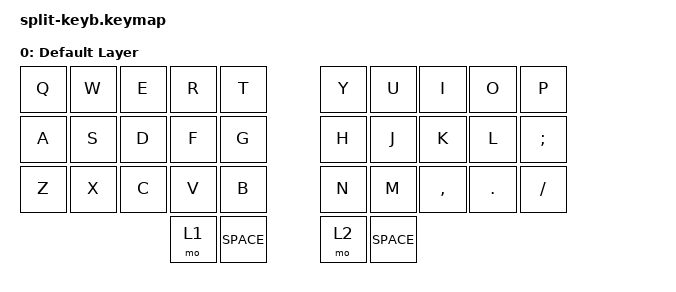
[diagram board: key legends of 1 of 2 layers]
#include <behaviors.dtsi>
#include <dt-bindings/zmk/keys.h>
#include <dt-bindings/zmk/bt.h>

/ {
    keymap {
                compatible = "zmk,keymap";

                default_layer {
                        display-name = "Default Layer";
// -------------------------------------------------------------------
// |  Q  |  W  |  E  |  R  |  T  |   |  Y  |  U   |  I  |  O  |  P  |
// |  A  |  S  |  D  |  F  |  G  |   |  H  |  J   |  K  |  L  |  ;  |
// |  Z  |  X  |  C  |  V  |  B  |   |  N  |  M   |  ,  |  .  |  /  |
    bindings = <
   &kp Q &kp W &kp E &kp R &kp T   &kp Y &kp U  &kp I     &kp O   &kp P
   &kp A &kp S &kp D &kp F &kp G   &kp H &kp J  &kp K     &kp L   &kp SEMI
   &kp Z &kp X &kp C &kp V &kp B   &kp N &kp M  &kp COMMA &kp DOT &kp FSLH
               &mo 1 SPACE                      &mo 2 SPACE
                  >;
            };

            lower_layer {
                display-name = "Lower Layer";
// --------------------------------------------------------------------
// |  1  |  2  |  3  |  4  |  5  |   |  6  |  7   |  8  |  9  |  0  |
// | BTCLR| BT1 | BT2 | BT3 | BT4 | BT5 |   | LFT | DWN |  UP | RGT |  
// |     |     |     |     |     |   |     |      |     |     |     |                
    bindings = <
    &kp TAB    &kp N1       &kp N2       &kp N3       &kp N4       &kp N5         &kp N6   &kp N7   &kp N8 &kp N9    &kp N0
    &bt BT_CLR &bt BT_SEL 0 &bt BT_SEL 1 &bt BT_SEL 2 &bt BT_SEL 3 &bt BT_SEL 4   &kp LEFT &kp DOWN &kp UP &kp RIGHT
    >;           
            };
    
    raise_layer {
                        display-name = "Raise Layer";
// -----------------------------------------------------------------------------------------
// |  !  |  @  |  #  |  $  |  %  |   |  ^  |  &  |  *  |  (  |  )  |
// |     |     |     |     |     |   |  -  |  =  |  [  |  ]  |  \  |
// |    |     |     |     |     |   |  _  |  +  |  {  |  }  | "|" |
    bindings = <
   &kp EXCL &kp AT &kp HASH &kp DLLR &kp PRCNT   &kp CARET &kp AMPS  &kp ASTRK &kp LPAR &kp RPAR
   &trans   &trans &trans   &trans   &trans      &kp MINUS &kp EQUAL &kp LBKT  &kp RBKT &kp BSLH
   &trans   &trans &trans   &trans   &trans      &kp UNDER &kp PLUS  &kp LBRC  &kp RBRC &kp PIPE

    };
};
